# GBA register map
File version: 0.5
Game Boy Advance SVD File for my Louise library
Registers are 16-bit, read-write, reset 0x0 unless marked. A register's access mark holds for its fields unless they carry their own. Offsets are from the block's base; lines under a group give offsets from that group; [hi:lo] are bit positions; {n}, {i} and the like mark numbered series; 'fields as' and 'values as' point back to an identical list; <NAME> marks a mode.

## Memory map
0x04000000 LCD size 0x56 — LCD I/O Registers
0x04000060 Sound size 0x48 — GBA Sound Controller
0x040000B0 DMA size 0x30 — DMA Transfer Channels
0x04000100 Timer size 0x10 — Timers registers
0x04000120 SerialCommunication size 0x3A — GBA Communication Ports
0x04000130 Inputs size 0x4 — Keypad Input
0x04000200 Interrupt size 0xA — Interrupt, Waitstate, and Power-Down Control

## DMA — DMA Transfer Channels
Base 0x040000B0
{0x0+0x12*i} DMA[{i}] (i=0..3) group — DMA [{i}] Transfer Channel
  0x00 SAD 32-bit wo — DMA Source Address
  0x04 DAD 32-bit wo — DMA Destination Address
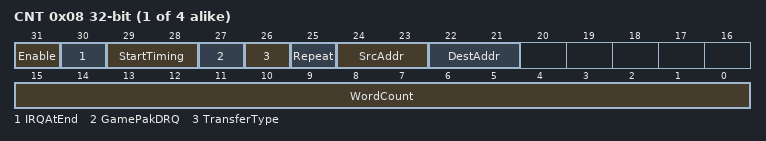
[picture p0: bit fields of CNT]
  0x08 CNT 32-bit — DMA Control
    [31] Enable — DMA Enable, after changing the Enable bit from 0 to 1, wait 2 clock cycles before accessing any DMA related registers.
    [30] IRQAtEnd — IRQ upon end of Word Count
    [29:28] StartTiming — DMA Start Timing
      0=Immediately; 1=VBlank; 2=HBlank; 3=Special (DMA0=Prohibited, DMA1/DMA2=Sound FIFO, DMA3=Video Capture)
    [27] GamePakDRQ — DMA3 only
    [26] TransferType — DMA Transfer Type
    [25] Repeat — DMA Repeat, must be zero if GamePak DRQ enabled
    [24:23] SrcAddr — Source Address Control
      0=Increment; 1=Decrement; 2=Fixed; 3=Prohibited
    [22:21] DestAddr — Dest Address Control
      0=Increment; 1=Decrement; 2=Fixed; 3=Increment_Reload
    [15:0] WordCount wo — Specifies the number of data units to be transferred, each unit is 16bit or 32bit depending on the transfer type, a value of zero is treated as max length (ie. 4000h, or 10000h for DMA3).

## Timer — Timers registers
Base 0x04000100
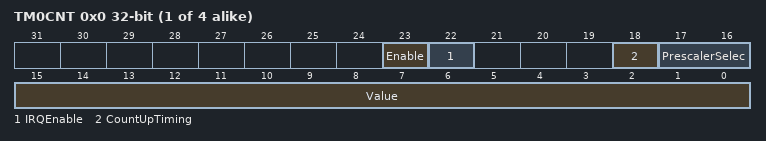
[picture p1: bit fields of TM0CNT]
{0x0+4i} TM{i}CNT (i=0..3) 32-bit — Timer {i} Counter/Reload and Control
  [23] Enable — Timer Start/Stop (0=Stop, 1=Operate)
  [22] IRQEnable — If set to 1, IRQ on Timer overflow
  [18] CountUpTiming — When Count-up Timing is enabled, the prescaler value is ignored, instead the time is incremented each time when the previous counter overflows. This function cannot be used for Timer 0 (as it is the first timer).
  [17:16] PrescalerSelec — Prescaler Selection
    0=F1; 1=F64; 2=F256; 3=F1024
  [15:0] Value — Timer Counter/Reload

## Inputs — Keypad Input
Base 0x04000130
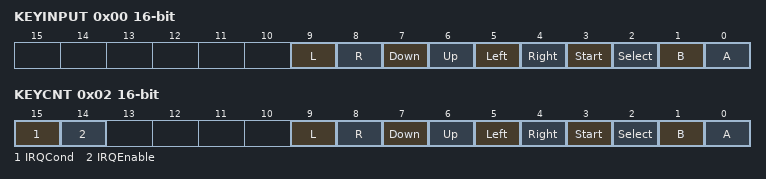
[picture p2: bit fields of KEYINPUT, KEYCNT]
0x00 KEYINPUT ro — Key Status
  [all] fields
    0=Pressed; 1=Released
  [9] L — Button L
  [8] R — Button R
  [7] Down — Button Down
  [6] Up — Button Up
  [5] Left — Button Left
  [4] Right — Button Right
  [3] Start — Button Start
  [2] Select — Button Select
  [1] B — Button B
  [0] A — Button A
0x02 KEYCNT — Key Interrupt Control
  [15] IRQCond — IRQ Condition
    0=LogicalOR; 1=LogicalAND
  [14] IRQEnable — IRQ Enable Flag
    0=Disable; 1=Enable
  [9] L — Button L
    0=Ignore; 1=Select
  [8] R — Button R
    0=Ignore; 1=Select
  [7] Down — Button Down
    0=Ignore; 1=Select
  [6] Up — Button Up
    0=Ignore; 1=Select
  [5] Left — Button Left
    0=Ignore; 1=Select
  [4] Right — Button Right
    0=Ignore; 1=Select
  [3] Start — Button Start
    0=Ignore; 1=Select
  [2] Select — Button Select
    0=Ignore; 1=Select
  [1] B — Button B
    0=Ignore; 1=Select
  [0] A — Button A
    0=Ignore; 1=Select

## Interrupt — Interrupt, Waitstate, and Power-Down Control
Base 0x04000200
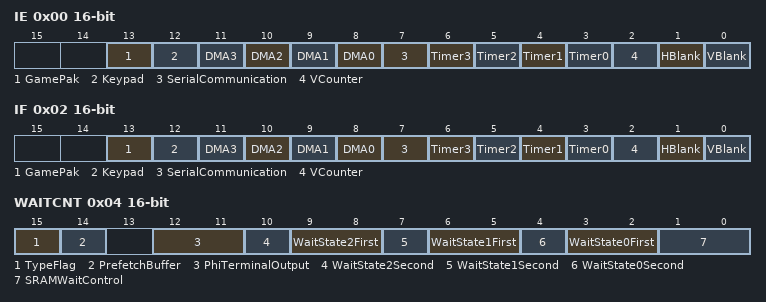
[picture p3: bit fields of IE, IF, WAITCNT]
0x00 IE — Interrupt Enable Register
  [13] GamePak, [12] Keypad, [n+8] DMA{n} (n=0..3), [7] SerialCommunication, [n+3] Timer{n} (n=0..3), [2] VCounter, [1] HBlank, [0] VBlank
0x02 IF — Interrupt Request Flags / IRQ Acknowledge
  fields as IE
0x04 WAITCNT — Waitstate Control
  [15] TypeFlag ro — Game Pak Type Flag
    0=GBA; 1=CGB
  [14] PrefetchBuffer — Game Pak Prefetch Buffer (Pipe)
  [12:11] PhiTerminalOutput — PHI Terminal Output (0..3 = Disable, 4.19MHz, 8.38MHz, 16.78MHz)
  [10] WaitState2Second — Wait State 2 Second Access (0..1 = 8,1 cycles; unlike above WS0,WS1)
  [9:8] WaitState2First — Wait State 2 First Access (0..3 = 4,3,2,8 cycles)
  [7] WaitState1Second — Wait State 1 Second Access (0..1 = 4,1 cycles; unlike above WS0)
  [6:5] WaitState1First — Wait State 1 First Access (0..3 = 4,3,2,8 cycles)
  [4] WaitState0Second — Wait State 0 Second Access (0..1 = 2,1 cycles)
  [3:2] WaitState0First — SWait State 0 First Access (0..3 = 4,3,2,8 cycles)
  [1:0] SRAMWaitControl — SRAM Wait Control (0..3 = 4,3,2,8 cycles)
0x08 IME — Interrupt Master Enable
  [0] MasterFlag — If set triggers Interrupts in IE Registers
